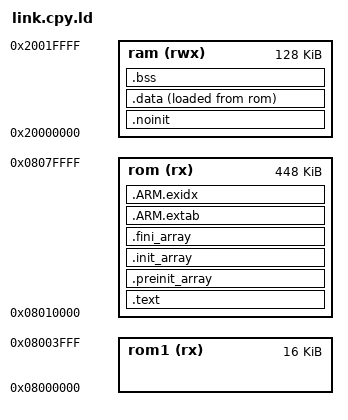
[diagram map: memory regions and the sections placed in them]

/* actual f407 */

/* Define memory regions. */
MEMORY
{

	rom1 (rx) : ORIGIN = 0x08000000, LENGTH = 16K
	rom (rx) : ORIGIN = 0x08010000 , LENGTH = 448K   /* ie. 512 - 64 */

	ram (rwx) : ORIGIN = 0x20000000, LENGTH = 128K
}

/* Include the common ld script. */
/* // INCLUDE cortex-m-generic.ld */

/* Enforce emmition of the vector table. */
EXTERN (vector_table)

/* Define the entry point of the output file. */
ENTRY(reset_handler)

/* Define sections. */
SECTIONS
{


/*
  It needs to binaries - because openocd flash_write always writes over even empty sections.

  --------
  OK. we have it working whereby flash doesn't overwrite rom1.
  We need two binaries. one binary to flash just the vector table at 0x08000000
  and then another binary to flash with program code at 0x08010000

  now we can write code quickly at 0x08010000
  Use. 
    objdump -h main.elf 

  to confirm where the image starts.
  Needs some easy way to build a two binary solution.

	.whoot : {
		*(.vectors)

	} >rom1

*/


	.text : {

		*(.text*)	/* Program code */
		. = ALIGN(4);
		*(.rodata*)	/* Read-only data */
		. = ALIGN(4);
	} >rom

	/* C++ Static constructors/destructors, also used for __attribute__
	 * ((constructor)) and the likes */
	.preinit_array : {
		. = ALIGN(4);
		__preinit_array_start = .;
		KEEP (*(.preinit_array))
		__preinit_array_end = .;
	} >rom
	.init_array : {
		. = ALIGN(4);
		__init_array_start = .;
		KEEP (*(SORT(.init_array.*)))
		KEEP (*(.init_array))
		__init_array_end = .;
	} >rom
	.fini_array : {
		. = ALIGN(4);
		__fini_array_start = .;
		KEEP (*(.fini_array))
		KEEP (*(SORT(.fini_array.*)))
		__fini_array_end = .;
	} >rom

	/*
	 * Another section used by C++ stuff, appears when using newlib with
	 * 64bit (long long) printf support
	 */
	.ARM.extab : {
		*(.ARM.extab*)
	} >rom
	.ARM.exidx : {
		__exidx_start = .;
		*(.ARM.exidx*)
		__exidx_end = .;
	} >rom

	. = ALIGN(4);
	_etext = .;

	/* ram, but not cleared on reset, eg boot/app comms */
	.noinit (NOLOAD) : {
		*(.noinit*)
	} >ram
	. = ALIGN(4);

	.data : {
		_data = .;
		*(.data*)	/* Read-write initialized data */
		*(.ramtext*)    /* "text" functions to run in ram */
		. = ALIGN(4);
		_edata = .;
	} >ram AT >rom
	_data_loadaddr = LOADADDR(.data);

	.bss : {
		*(.bss*)	/* Read-write zero initialized data */
		*(COMMON)
		. = ALIGN(4);
		_ebss = .;
	} >ram

	/*
	 * The .eh_frame section appears to be used for C++ exception handling.
	 * You may need to fix this if you're using C++.
	 */
	/DISCARD/ : { *(.eh_frame) }

	. = ALIGN(4);
	end = .;
}

PROVIDE(_stack = ORIGIN(ram) + LENGTH(ram));

